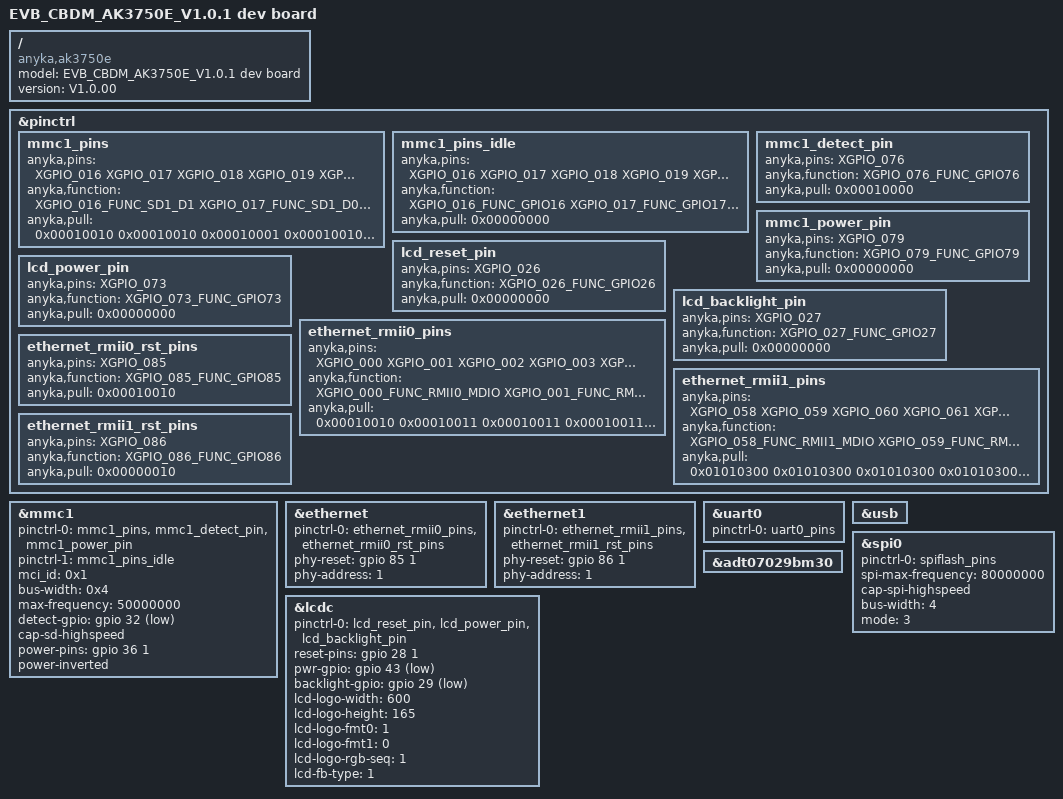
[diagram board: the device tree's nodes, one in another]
/*
 * Anycloud37e develop board dts
 *
 * Copyright (C) 2020 Anyka(Guangzhou) Microelectronics Technology Co., Ltd.
 *
 * This program is free software; you can redistribute it and/or modify
 * it under the terms of the GNU General Public License as published by
 * the Free Software Foundation; either version 2 of the License, or
 * (at your option) any later version.
 *
 * This program is distributed in the hope that it will be useful,
 * but WITHOUT ANY WARRANTY; without even the implied warranty of
 * MERCHANTABILITY or FITNESS FOR A PARTICULAR PURPOSE.  See the
 * GNU General Public License for more details.
 */

/dts-v1/;
#include "anycloud_ak37e.dtsi"
#include "anycloud_ak37e_lcd.dtsi"
#include "anycloud_ak37e_pinctrl.dtsi"

/ {
    compatible = "anyka,ak3750e";
    model = "EVB_CBDM_AK3750E_V1.0.1 dev board";
    version = "V1.0.00";
};

&pinctrl {
    /*
    * "anyka,function": func index, please refer to dt-bindings/pinctrl/ak_37e_pinctrl.h
    * "anyka,pull": configuration of the pins
    * bit[7:0]: pull up/down configuration
    *     bit[0]: pull up or pull down selection, 1 means select pull down, 0 means select pull up
    *     bit[4]: pull up or pull down enable, 1 means enable pull up&down function, 0 means disable fuction
    * !!! Notice that not all pin support pull up and pull down. Please refer to the programer's guide.
    * bit[15:8]: driver strength configuration.
    *     bit[9:8] drive strength.
    * bit[23:16]: input enable configuration
    *     bit[16]: 1 means enable input, 0 means disable input.
    * bit[31:24]: pin slew rate configuration
    *     bit[24]: 1 means enable slew rate, 0 means disable slew rate.
    * !!! Notice OTHER bits which not mentioned please set to 0.
    */

    mmc1_pins: mmc1_pins {
        anyka,pins = <XGPIO_016 XGPIO_017 XGPIO_018 XGPIO_019 XGPIO_020 XGPIO_021>;
        anyka,function = <XGPIO_016_FUNC_SD1_D1
                            XGPIO_017_FUNC_SD1_D0
                            XGPIO_018_FUNC_SD1_MCLK
                            XGPIO_019_FUNC_SD1_CMD
                            XGPIO_020_FUNC_SD1_D3
                            XGPIO_021_FUNC_SD1_D2>;
        anyka,pull = <0x00010010 0x00010010 0x00010001 0x00010010 0x00010010 0x00010010>;
    };

    mmc1_pins_idle: mmc1_pins_idle {
        anyka,pins = <XGPIO_016 XGPIO_017 XGPIO_018 XGPIO_019 XGPIO_020 XGPIO_021>;
        anyka,function = <XGPIO_016_FUNC_GPIO16
                            XGPIO_017_FUNC_GPIO17
                            XGPIO_018_FUNC_GPIO18
                            XGPIO_019_FUNC_GPIO19
                            XGPIO_020_FUNC_GPIO20
                            XGPIO_021_FUNC_GPIO21>;
        anyka,pull = <0x00000000>;
    };


    mmc1_detect_pin: mmc1_detect_pin {
        anyka,pins = <XGPIO_076>;
        anyka,function = <XGPIO_076_FUNC_GPIO76>;
        anyka,pull = <0x00010000>;
    };

    mmc1_power_pin: mmc1_power_pin {
        anyka,pins = <XGPIO_079>;
        anyka,function = <XGPIO_079_FUNC_GPIO79>;
        anyka,pull = <0x00000000>;
    };

    lcd_reset_pin: lcd_reset_pin {
        anyka,pins = <XGPIO_026>;
        anyka,function = <XGPIO_026_FUNC_GPIO26>;
        anyka,pull = <0x00000000>;
    };

    lcd_power_pin: lcd_power_pin {
        anyka,pins = <XGPIO_073>;
        anyka,function = <XGPIO_073_FUNC_GPIO73>;
        anyka,pull = <0x00000000>;
    };

    lcd_backlight_pin: lcd_backlight_pin {
        anyka,pins = <XGPIO_027>;
        anyka,function = <XGPIO_027_FUNC_GPIO27>;
        anyka,pull = <0x00000000>;
    };


    ethernet_rmii0_pins: ethernet_rmii0_pins {
        anyka,pins = <XGPIO_000
                        XGPIO_001
                        XGPIO_002
                        XGPIO_003
                        XGPIO_004
                        XGPIO_005
                        XGPIO_006
                        XGPIO_007
                        XGPIO_008
                        XGPIO_009>;
        anyka,function = <XGPIO_000_FUNC_RMII0_MDIO
                            XGPIO_001_FUNC_RMII0_MDC
                            XGPIO_002_FUNC_RMII0_RXER
                            XGPIO_003_FUNC_RMII0_RXDV
                            XGPIO_004_FUNC_RMII0_RXD0
                            XGPIO_005_FUNC_RMII0_RXD1
                            XGPIO_006_FUNC_OPCLK0
                            XGPIO_007_FUNC_RMII0_TXD0
                            XGPIO_008_FUNC_RMII0_TXD1
                            XGPIO_009_FUNC_RMII0_TXEN
                            >;
        anyka,pull = <0x00010010 0x00010011 0x00010011 0x00010011 0x00010011 0x00010011 0x00010300 0x00010011 0x00010011 0x00010011>;
    };

    ethernet_rmii1_pins: ethernet_rmii1_pins {
        anyka,pins = <XGPIO_058
                        XGPIO_059
                        XGPIO_060
                        XGPIO_061
                        XGPIO_062
                        XGPIO_063
                        XGPIO_064
                        XGPIO_065
                        XGPIO_066
                        XGPIO_067>;
        anyka,function = <XGPIO_058_FUNC_RMII1_MDIO
                            XGPIO_059_FUNC_RMII1_MDC
                            XGPIO_060_FUNC_RMII1_RXER
                            XGPIO_061_FUNC_RMII1_RXDV
                            XGPIO_062_FUNC_RMII1_RXD0
                            XGPIO_063_FUNC_RMII1_RXD1
                            XGPIO_064_FUNC_OPCLK1
                            XGPIO_065_FUNC_RMII1_TXD0
                            XGPIO_066_FUNC_RMII1_TXD1
                            XGPIO_067_FUNC_RMII1_TXEN
                            >;
		anyka,pull = <0x01010300 0x01010300 0x01010300 0x01010300 0x01010300 0x01010300 0x01010310 0x01010300 0x01010300 0x01010300>;
    };

    ethernet_rmii0_rst_pins: ethernet_rmii0_rst_pins {
        anyka,pins = <XGPIO_085>;
        anyka,function = <XGPIO_085_FUNC_GPIO85>;
        anyka,pull = <0x00010010>;
    };

    ethernet_rmii1_rst_pins: ethernet_rmii1_rst_pins {
        anyka,pins = <XGPIO_086>;
        anyka,function = <XGPIO_086_FUNC_GPIO86>;
        anyka,pull = <0x00000010>;
    };
};
&mmc1 {
    pinctrl-names = "default","idle";
    pinctrl-0 = <&mmc1_pins &mmc1_detect_pin &mmc1_power_pin>;
    pinctrl-1 = <&mmc1_pins_idle>;
	mci_id = <0x1>;  //for mmc id
    bus-width = <0x4>;
    max-frequency = <50000000>;
    /*
     *  detect mode:
     *  (1) non-removable;
     *  (2) detect-gpio/detect-gpios: card detect using gpio
     *      for example:
     *      detect-gpio = <&gpio 76 1>;  or detect-gpios = <&gpio 76 1>;
     *  (3) cd_clk: card detect using MCLK
     */
    detect-gpio = <&gpio 32 1>;

    /* if support highspeed, using cap-sd-highspeed */
    cap-sd-highspeed;

	/*
	 * support tf card circuit enable function
	 */
	power-pins = <&gpio 36 1>;
	power-inverted;
	status = "okay";
};


&ethernet {
    pinctrl-names = "default";
	pinctrl-0 = <&ethernet_rmii0_pins &ethernet_rmii0_rst_pins>;
    phy-reset = <&gpio 85 1>;
	phy-address = <1>;

	status = "okay";

};


&ethernet1 {
    pinctrl-names = "default";
	pinctrl-0 = <&ethernet_rmii1_pins &ethernet_rmii1_rst_pins>;
    phy-reset = <&gpio 86 1>;
	phy-address = <1>;

	status = "okay";

};
&uart0 {
    pinctrl-names = "default";
    pinctrl-0 = <&uart0_pins>;
    status = "okay";
};

&usb {
   status = "okay";
};

&spi0 {
    pinctrl-names = "default";
    pinctrl-0 = <&spiflash_pins>;
     /*pinctrl-names = "default";*/
     /*pinctrl-0 = <&spiflash_pins>;*/
    spi-max-frequency = <80000000>;
    /*
     * cap-spi-highspeed;
     * if defined, means high speed controller(Maximum 80M/s);
     * if not, means normal speed controller(below 60M/s)
     */
    cap-spi-highspeed;
    /* spi flash data bus width:
        ** 1 means 1 wire mode.
        ** 2 means 2 wire mode
        ** 4 means 4 wire mode.
        ** default: 4 wire mode.
        **/
    bus-width = <4>;
    mode = <3>; /* spi mode selected  */
    status = "okay";
};

/* MIPI panel*/
&lcdc {
    pinctrl-names = "default";
    pinctrl-0 = <&lcd_reset_pin &lcd_power_pin &lcd_backlight_pin>;
    reset-pins      = <&gpio 28 1>;
    pwr-gpio        = <&gpio 43 1>;
    backlight-gpio  = <&gpio 29 1>;

    lcd-logo-width = <600>;
    lcd-logo-height = <165>;
    //[fmt1:fmt0] 00 16bits input(RGB565 or BGR565)
    //[fmt1:fmt0] 01 24bits input(RGB888 or BGR888)
    //[fmt1:fmt0] 10 or 11 32bits input(ARGB888 ABGR888 RGBA888 BGRA888)
    lcd-logo-fmt0 = <1>;
    lcd-logo-fmt1 = <0>;
    lcd-logo-rgb-seq = <1>; //0 for BGR, 1 for RGB

    lcd-fb-type = <1>; //0:single buffer; 1:double buffer
    status = "okay";
};

/* 7 inch mipi */
&adt07029bm30 {
    status = "okay";
};

/* 10 inch mipi */
/*
&sat101md40i32br1 {
    status = "okay";
};
*/

